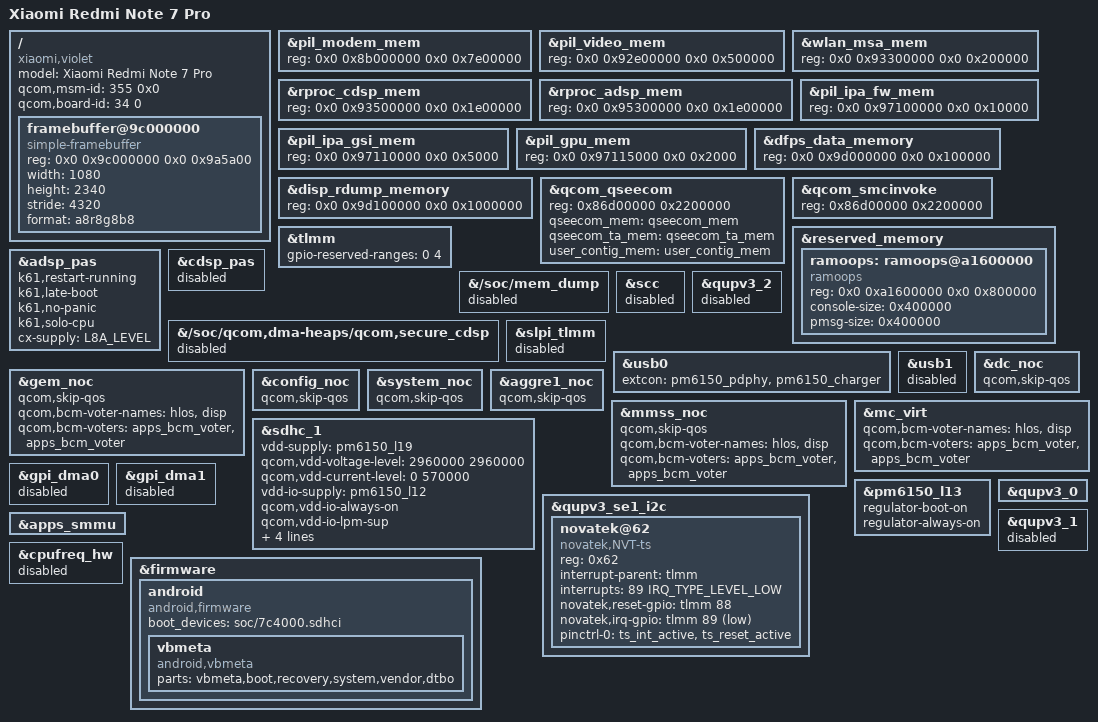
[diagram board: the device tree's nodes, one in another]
// SPDX-License-Identifier: GPL-2.0-only
/dts-v1/;

#include "sm6150.dtsi"
#include "violet-pm6150.dtsi"
#include "violet-battery.dtsi"
#include "violet-pm6150l.dtsi"
#include "violet-sm6150-sde.dtsi"
#include "violet-display.dtsi"
#include "sm6150-gpu.dtsi"
#include "sm6150-gpu-pwrlevels.dtsi"

/ {
	model = "Xiaomi Redmi Note 7 Pro";
	compatible = "xiaomi,violet", "qcom,sm6150";
	qcom,msm-id = <355 0x0>;
	qcom,board-id = <34 0>;
};

/*
 * sm6150.dtsi carries SA6155 values. Xiaomi moved these regions, so every
 * address here comes from the running phone (/sys/firmware/fdt on 4.14),
 * not from the node names, which are stale in both trees.
 */
&pil_modem_mem {
	reg = <0x0 0x8b000000 0x0 0x7e00000>;
};

&pil_video_mem {
	reg = <0x0 0x92e00000 0x0 0x500000>;
};

&wlan_msa_mem {
	reg = <0x0 0x93300000 0x0 0x200000>;
};

&rproc_cdsp_mem {
	reg = <0x0 0x93500000 0x0 0x1e00000>;
};

&rproc_adsp_mem {
	reg = <0x0 0x95300000 0x0 0x1e00000>;
};

&pil_ipa_fw_mem {
	reg = <0x0 0x97100000 0x0 0x10000>;
};

&pil_ipa_gsi_mem {
	reg = <0x0 0x97110000 0x0 0x5000>;
};

&pil_gpu_mem {
	reg = <0x0 0x97115000 0x0 0x2000>;
};

&dfps_data_memory {
	reg = <0x0 0x9d000000 0x0 0x100000>;
};

&disp_rdump_memory {
	reg = <0x0 0x9d100000 0x0 0x1000000>;
};

&qcom_qseecom {
	reg = <0x86d00000 0x2200000>;
};

&qcom_smcinvoke {
	reg = <0x86d00000 0x2200000>;
};

/*
 * Same layout as stock 4.14, which reads this log back after a failed boot:
 * console at +0, pmsg at +4M. earlycon=ramoops in violet.config uses the pmsg
 * zone, and 4.14 shows it as pmsg-ramoops-0.
 */
&reserved_memory {
	ramoops: ramoops@a1600000 {
		compatible = "ramoops";
		reg = <0x0 0xa1600000 0x0 0x800000>;
		console-size = <0x400000>;
		pmsg-size = <0x400000>;
	};
};

/* Reads of these hang the CPU: they belong to the secure world */
&tlmm {
	gpio-reserved-ranges = <0 4>;
};

/*
 * ADSP: firmware is on the modem partition; boot with
 * firmware_class.path=/vendor/firmware,/vendor/firmware_mnt/image. Under
 * kexec the DSP is already running, so stop it through TZ first and boot it
 * from a thread once the partition is mounted.
 */
&adsp_pas {
	status = "okay";
	k61,restart-running;
	k61,late-boot;
	k61,no-panic;
	k61,solo-cpu;
	/*
	 * The driver asks for a regulator named \"cx\" (reg-names), but the node only
	 * had vdd_cx-supply, so it got a dummy and the ADSP rail (lcx.lvl, retention
	 * at reset) was never voted to TURBO for boot as 4.14 does.
	 */
	cx-supply = <&L8A_LEVEL>;
};

&cdsp_pas {
	status = "disabled";
};

/*
 * DEBUG: bring-up console on the panel. ABL leaves the video-mode panel
 * scanning out the splash buffer, so fbcon can draw the kernel log there
 * with no display driver. 1080x2340, 32 bpp.
 */
/ {
	framebuffer@9c000000 {
		compatible = "simple-framebuffer";
		reg = <0x0 0x9c000000 0x0 0x9a5a00>;
		width = <1080>;
		height = <2340>;
		stride = <4320>;
		format = "a8r8g8b8";
	};
};

/*
 * DEBUG: mem_dump_driver_init hangs (kexec from 4.14, run 03 attempt 5),
 * most likely in its TZ dump-table registration. Crash-dump aid only.
 */
&{/soc/mem_dump} {
	status = "disabled";
};

/*
 * DEBUG (kexec only): 4.14 has already given this carveout to the secure
 * side, so taking it over from HLOS stalls (run 03 attempt 6).
 */
&{/soc/qcom,dma-heaps/qcom,secure_cdsp} {
	status = "disabled";
};

/*
 * violet has no powered sensor subsystem (sensors live on the ADSP); 4.14
 * keeps these SA6155 SSC blocks disabled. Probing the SCC hung every CPU
 * right after gpu_cc (run 03 attempts 9 to 11).
 */
&scc {
	status = "disabled";
};

&qupv3_2 {
	status = "disabled";
};

&slpi_tlmm {
	status = "disabled";
};

/*
 * Type-C: the pdphy policy engine reports VBUS/role through its extcon
 * (smb5 only drives its own for micro-USB). dwc3 keeps the SoC default
 * dr_mode = "otg" + usb-role-switch: in peripheral-only mode dwc3-msm
 * ignores extcon VBUS events, and without the role switch it never
 * reaches LPM, so it never starts the gadget (run 03 attempts 98-103).
 */
&usb0 {
	status = "okay";
	extcon = <&pm6150_pdphy>, <&pm6150_charger>;
};

&usb1 {
	status = "disabled";
};


/*
 * DEBUG (run 03): probing 1700000.interconnect (aggre1_noc) hangs the CPU
 * with IRQs off, in the QoS programming (tables are SA6155 automotive:
 * EMAC AVB, PCIe, ... masters that do not exist on SM6150).
 */
&dc_noc {
	qcom,skip-qos;
};

&gem_noc {
	qcom,skip-qos;
};

&config_noc {
	qcom,skip-qos;
};

&system_noc {
	qcom,skip-qos;
};

&aggre1_noc {
	qcom,skip-qos;
};

&mmss_noc {
	qcom,skip-qos;
};

/*
 * DEBUG (run 03): after kexec the display block is powered down and
 * disp_rsc (af20000) reads PRNT_CHLD_CONFIG = 0 -> probe -EINVAL, so
 * disp_bcm_voter never appears and the nocs below defer forever.
 * Vote through the apps voter only for now.
 */
&mc_virt {
	qcom,bcm-voter-names = "hlos", "disp";
	qcom,bcm-voters = <&apps_bcm_voter>, <&apps_bcm_voter>;
};

&gem_noc {
	qcom,bcm-voter-names = "hlos", "disp";
	qcom,bcm-voters = <&apps_bcm_voter>, <&apps_bcm_voter>;
};

&mmss_noc {
	qcom,bcm-voter-names = "hlos", "disp";
	qcom,bcm-voters = <&apps_bcm_voter>, <&apps_bcm_voter>;
};

/* eMMC (4.14 atoll-idp.dtsi settings) */
&sdhc_1 {
	/*
	 * sdhci-msm bails out with "not boot dev" when the boot_conf fuse
	 * (SA6155 value in sm6150.dtsi) disagrees; eMMC is the only storage
	 * on violet, so drop the check.
	 */
	/delete-property/ nvmem-cells;
	/delete-property/ nvmem-cell-names;
	/delete-property/ boot_device_type;
	/delete-property/ interconnects;
	/delete-property/ interconnect-names;
	vdd-supply = <&pm6150_l19>;
	qcom,vdd-voltage-level = <2960000 2960000>;
	qcom,vdd-current-level = <0 570000>;

	vdd-io-supply = <&pm6150_l12>;
	qcom,vdd-io-always-on;
	qcom,vdd-io-lpm-sup;
	qcom,vdd-io-voltage-level = <1800000 1800000>;
	qcom,vdd-io-current-level = <0 325000>;

	pinctrl-names = "active", "sleep";
	pinctrl-0 = <&sdc1_on>;
	pinctrl-1 = <&sdc1_off>;

	status = "okay";
};


/* attempt 40 bisect: gpi dma off */
&gpi_dma0 {
	status = "disabled";
};

&gpi_dma1 {
	status = "disabled";
};

/*
 * Panel VDDIO (4.14 dsi display vddio-supply). It also powers the pull-ups
 * of the touch I2C bus and the NT36672A TDDI I/O: with it off, SDA/SCL sit
 * low and every transfer times out (run 03 attempts 110/111). Kept on until
 * the display driver manages it.
 */
&pm6150_l13 {
	regulator-boot-on;
	regulator-always-on;
};

/*
 * QUP0: only SE1 (I2C bus of the NT36672A TDDI touch, 4.14 i2c@884000)
 * is enabled for now.
 */
&qupv3_0 {
	status = "okay";
};

&qupv3_se1_i2c {
	status = "okay";

	/*
	 * Novatek NT36672A TDDI touch (this phone: NVT-ts bound at 1-0062 on
	 * 4.14; the Himax variant at 0x48 is left out). It is powered from the
	 * panel rails, so it may not answer until the display is up.
	 */
	novatek@62 {
		compatible = "novatek,NVT-ts";
		reg = <0x62>;
		interrupt-parent = <&tlmm>;
		interrupts = <89 IRQ_TYPE_LEVEL_LOW>;
		novatek,reset-gpio = <&tlmm 88 0x00>;
		novatek,irq-gpio = <&tlmm 89 0x2001>;
		pinctrl-names = "default";
		pinctrl-0 = <&ts_int_active &ts_reset_active>;
	};
};

&qupv3_1 {
	status = "disabled";
};

/* attempt 42: no icc path on apps_smmu */
&apps_smmu {
	/delete-property/ interconnects;
	/delete-property/ qcom,active-only;
};

/* attempt 49: no cpufreq-hw */
&cpufreq_hw {
	status = "disabled";
};

/*
 * Android first-stage init: by-name links and the AVB partition list, as
 * the 4.14 DT has them (vbmeta, no vbmeta_system: retrofit dynamic
 * partitions with super in "system"). The fstab comes from the ramdisk.
 */
&firmware {
	android {
		compatible = "android,firmware";
		boot_devices = "soc/7c4000.sdhci";

		vbmeta {
			compatible = "android,vbmeta";
			parts = "vbmeta,boot,recovery,system,vendor,dtbo";
		};
	};
};

/*
 * The 6.1 qseecom driver finds its heaps through these phandles; the
 * sm6150 node only has memory-region.
 */
&qcom_qseecom {
	qseecom_mem = <&qseecom_mem>;
	qseecom_ta_mem = <&qseecom_ta_mem>;
	user_contig_mem = <&user_contig_mem>;
};
